# ATmega8 device description
Architecture: AVR8; Family: megaAVR
Registers are 8-bit, access not given, no defined reset value unless marked. A register's access mark holds for its fields unless they carry their own. Offsets are from the block's base; [hi:lo] are bit positions; 'fields as' and 'values as' point back to an identical list.

## TC2 (TC8_ASYNC module) — Timer/Counter, 8-bit Async
Instances: TC2 0x00
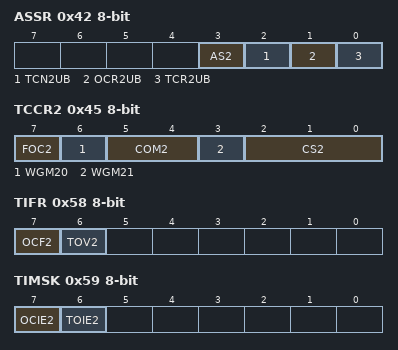
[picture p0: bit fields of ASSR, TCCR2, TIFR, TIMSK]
0x42 ASSR — Asynchronous Status Register
  [3] AS2 — Asynchronous Timer/counter2
  [2] TCN2UB — Timer/Counter2 Update Busy
  [1] OCR2UB — Output Compare Register2 Update Busy
  [0] TCR2UB — Timer/counter Control Register2 Update Busy
0x43 OCR2 — Timer/Counter2 Output Compare Register
0x44 TCNT2 — Timer/Counter2
0x45 TCCR2 — Timer/Counter2 Control Register
  [7] FOC2 — Force Output Compare
  [6] WGM20 — Waveform Genration Mode
    0=NORMAL; 2=PWM_PHASE_CORRECT; 1=CTC; 3=FAST_PWM
  [5:4] COM2 — Compare Output Mode bits
  [3] WGM21 — Waveform Generation Mode
  [2:0] CS2 — Clock Select bits
    0=NO_CLOCK_SOURCE_STOPPED; 1=RUNNING_NO_PRESCALING; 2=RUNNING_CLK_8; 3=RUNNING_CLK_32; 4=RUNNING_CLK_64; 5=RUNNING_CLK_128; 6=RUNNING_CLK_256; 7=RUNNING_CLK_1024
0x50 SFIOR — Special Function IO Register
  [1] PSR2 — Prescaler Reset Timer/Counter2
0x58 TIFR — Timer/Counter Interrupt Flag Register
  [7] OCF2 — Output Compare Flag 2
  [6] TOV2 — Timer/Counter2 Overflow Flag
0x59 TIMSK — Timer/Counter Interrupt Mask register
  [7] OCIE2 — Timer/Counter2 Output Compare Match Interrupt Enable
  [6] TOIE2 — Timer/Counter2 Overflow Interrupt Enable

## USART
Instances: USART 0x00
0x29 UBRRL — USART Baud Rate Register Low Byte
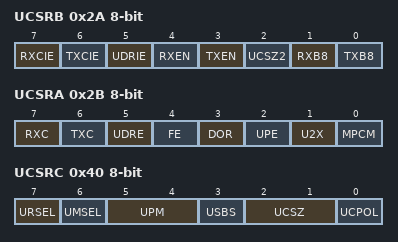
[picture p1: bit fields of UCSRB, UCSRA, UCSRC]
0x2A UCSRB — USART Control and Status Register B
  [7] RXCIE — RX Complete Interrupt Enable
  [6] TXCIE — TX Complete Interrupt Enable
  [5] UDRIE — USART Data register Empty Interrupt Enable
  [4] RXEN — Receiver Enable
  [3] TXEN — Transmitter Enable
  [2] UCSZ2 — Character Size
  [1] RXB8 — Receive Data Bit 8
  [0] TXB8 — Transmit Data Bit 8
0x2B UCSRA — USART Control and Status Register A
  [7] RXC — USART Receive Complete
  [6] TXC — USART Transmitt Complete
  [5] UDRE — USART Data Register Empty
  [4] FE — Framing Error
  [3] DOR — Data overRun
  [2] UPE — Parity Error
  [1] U2X — Double the USART transmission speed
  [0] MPCM — Multi-processor Communication Mode
0x2C UDR — USART I/O Data Register
0x40 UCSRC — USART Control and Status Register C
  [7] URSEL — Register Select
  [6] UMSEL — USART Mode Select
    0=ASYNCHRONOUS_OPERATION; 1=SYNCHRONOUS_OPERATION
  [5:4] UPM — Parity Mode Bits
    0=DISABLED; 2=ENABLED_EVEN_PARITY; 3=ENABLED_ODD_PARITY
  [3] USBS — Stop Bit Select
    0=1_BIT; 1=2_BIT
  [2:1] UCSZ — Character Size
  [0] UCPOL — Clock Polarity
0x40 UBRRH bits used 3:0 — USART Baud Rate Register Hight Byte

## TWI — Two Wire Serial Interface
Instances: TWI 0x00
0x20 TWBR — TWI Bit Rate register
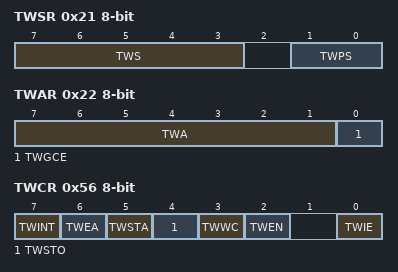
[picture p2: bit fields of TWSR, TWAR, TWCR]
0x21 TWSR — TWI Status Register
  [7:3] TWS (bit 3 of the value upward) — TWI Status
  [1:0] TWPS — TWI Prescaler
    0=1; 1=4; 2=16; 3=64
0x22 TWAR — TWI (Slave) Address register
  [7:1] TWA — TWI (Slave) Address register Bits
  [0] TWGCE — TWI General Call Recognition Enable Bit
0x23 TWDR — TWI Data register
0x56 TWCR — TWI Control Register
  [7] TWINT — TWI Interrupt Flag
  [6] TWEA — TWI Enable Acknowledge Bit
  [5] TWSTA — TWI Start Condition Bit
  [4] TWSTO — TWI Stop Condition Bit
  [3] TWWC — TWI Write Collition Flag
  [2] TWEN — TWI Enable Bit
  [0] TWIE — TWI Interrupt Enable

## WDT — Watchdog Timer
Instances: WDT 0x00
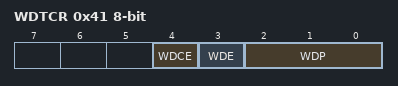
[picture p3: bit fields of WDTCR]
0x41 WDTCR — Watchdog Timer Control Register
  [4] WDCE — Watchdog Change Enable
  [3] WDE — Watch Dog Enable
  [2:0] WDP — Watch Dog Timer Prescaler bits
    0=OSCILLATOR_CYCLES_16K; 1=OSCILLATOR_CYCLES_32K; 2=OSCILLATOR_CYCLES_64K; 3=OSCILLATOR_CYCLES_128K; 4=OSCILLATOR_CYCLES_256K; 5=OSCILLATOR_CYCLES_512K; 6=OSCILLATOR_CYCLES_1024K; 7=OSCILLATOR_CYCLES_2048K

## PORTB — I/O Port
Instances: PORTB 0x00
0x36 PINB — Port B Input Pins
0x37 DDRB — Port B Data Direction Register
0x38 PORTB — Port B Data Register

## PORTC — I/O Port
Instances: PORTC 0x00
0x33 PINC bits used 6:0 — Port C Input Pins
0x34 DDRC bits used 6:0 — Port C Data Direction Register
0x35 PORTC bits used 6:0 — Port C Data Register

## PORTD — I/O Port
Instances: PORTD 0x00
0x30 PIND — Port D Input Pins
0x31 DDRD — Port D Data Direction Register
0x32 PORTD — Port D Data Register

## EEPROM
Instances: EEPROM 0x00
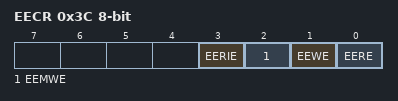
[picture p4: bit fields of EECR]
0x3C EECR — EEPROM Control Register
  [3] EERIE — EEPROM Ready Interrupt Enable
  [2] EEMWE — EEPROM Master Write Enable
  [1] EEWE — EEPROM Write Enable
  [0] EERE — EEPROM Read Enable
0x3D EEDR — EEPROM Data Register
0x3E EEAR 16-bit bits used 8:0 — EEPROM Address Register Bytes

## CPU — CPU Registers
Instances: CPU 0x00
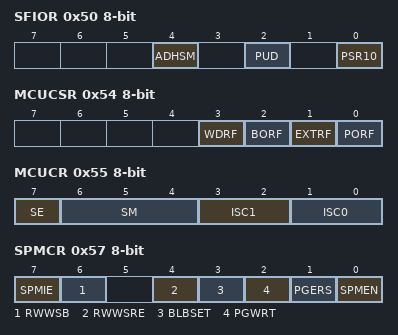
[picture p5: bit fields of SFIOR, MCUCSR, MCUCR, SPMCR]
0x50 SFIOR — Special Function IO Register
  [4] ADHSM — ADC High Speed Mode
  [2] PUD — Pull-up Disable
  [0] PSR10 — Prescaler Reset Timer/Counter1 and Timer/Counter0
0x51 OSCCAL — Oscillator Calibration Value
  [7:0] OSCCAL — Oscillator Calibration
0x54 MCUCSR — MCU Control And Status Register
  [3] WDRF — Watchdog Reset Flag
  [2] BORF — Brown-out Reset Flag
  [1] EXTRF — External Reset Flag
  [0] PORF — Power-on reset flag
0x55 MCUCR — MCU Control Register
  [7] SE — Sleep Enable
  [6:4] SM — Sleep Mode Select
    0=IDLE; 1=ADC (ADC Noise Reduction (If Available)); 2=PDOWN (Power Down); 3=PSAVE (Power Save); 6=STDBY (Standby)
  [3:2] ISC1 — Interrupt Sense Control 1 Bits
    0=LOW_LEVEL_OF_INTX; 1=ANY_LOGICAL_CHANGE_IN_INTX; 2=FALLING_EDGE_OF_INTX; 3=RISING_EDGE_OF_INTX
  [1:0] ISC0 — Interrupt Sense Control 0 Bits
    values as ISC1
0x57 SPMCR — Store Program Memory Control Register
  [7] SPMIE — SPM Interrupt Enable
  [6] RWWSB — Read-While-Write Section Busy
  [4] RWWSRE — Read-While-Write Section Read Enable
  [3] BLBSET — Boot Lock Bit Set
  [2] PGWRT — Page Write
  [1] PGERS — Page Erase
  [0] SPMEN — Store Program Memory Enable
0x5D SP 16-bit bits used 10:0 — Stack Pointer
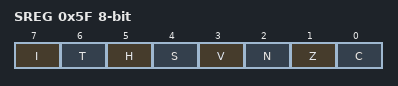
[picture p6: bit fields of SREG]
0x5F SREG — Status Register
  [7] I — Global Interrupt Enable
  [6] T — Bit Copy Storage
  [5] H — Half Carry Flag
  [4] S — Sign Bit
  [3] V — Two's Complement Overflow Flag
  [2] N — Negative Flag
  [1] Z — Zero Flag
  [0] C — Carry Flag
Value list OSCCAL_VALUE_ADDRESSES: 0=1_0_MHz; 1=2_0_MHz; 2=4_0_MHz; 3=8_0_MHz

## ADC — Analog-to-Digital Converter
Instances: ADC 0x00
0x24 ADC 16-bit — ADC Data Register Bytes
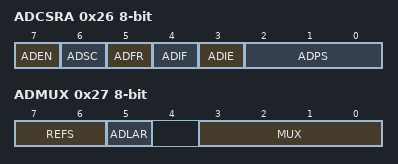
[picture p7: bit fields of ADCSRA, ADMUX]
0x26 ADCSRA — The ADC Control and Status register
  [7] ADEN — ADC Enable
  [6] ADSC — ADC Start Conversion
  [5] ADFR — ADC Free Running Select
  [4] ADIF — ADC Interrupt Flag
  [3] ADIE — ADC Interrupt Enable
  [2:0] ADPS — ADC Prescaler Select Bits
    0=2; 1=2; 2=4; 3=8; 4=16; 5=32; 6=64; 7=128
0x27 ADMUX — The ADC multiplexer Selection Register
  [7:6] REFS — Reference Selection Bits
    0=AREF_INTERNAL_VREF_TURNED_OFF; 1=AVCC_WITH_EXTERNAL_CAPACITOR_AT_AREF_PIN; 3=INTERNAL_2_56V_VOLTAGE_REFERENCE_WITH_EXTERNAL_CAPACITOR_AT_AREF_PIN
  [5] ADLAR — Left Adjust Result
  [3:0] MUX — Analog Channel and Gain Selection Bits
